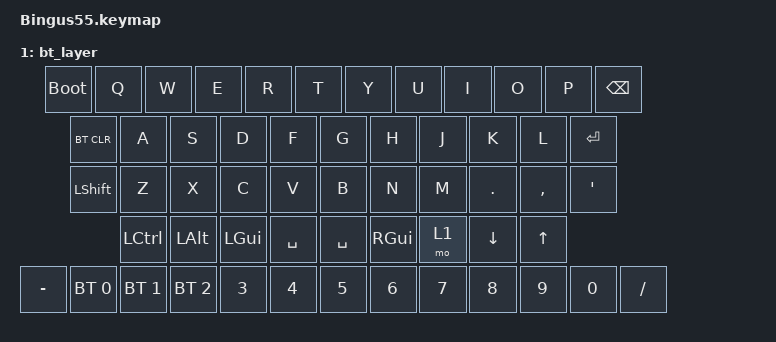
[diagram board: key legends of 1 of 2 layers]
#include <dt-bindings/zmk/keys.h>
#include <dt-bindings/zmk/bt.h>
#include <behaviors.dtsi>

/ {
    keymap {
            compatible = "zmk,keymap";

            default_layer {
                bindings = <
                &kp ESC &kp Q &kp W &kp E &kp R &kp T &kp Y &kp U &kp I &kp O &kp P &kp BSPC
		        &kp TAB &kp A &kp S &kp D &kp F &kp G &kp H &kp J &kp K &kp L &kp ENTER 
	            &kp LSHIFT &kp Z &kp X &kp C &kp V &kp B &kp N &kp M &kp DOT &kp COMMA &kp APOS 
		        &kp LCTRL &kp LALT &kp LGUI &kp SPACE &kp SPACE &kp RGUI &mo 1 &kp LEFT &kp RIGHT
		        &kp MINUS &kp N1 &kp N2 &kp N3 &kp N4 &kp N5 &kp N6 &kp N7 &kp N8 &kp N9 &kp N0 &kp SLASH
                >;
            };

            bt_layer {
                bindings = <
                    &bootloader &kp Q &kp W &kp E &kp R &kp T &kp Y &kp U &kp I &kp O &kp P &kp BSPC
		        &bt BT_CLR &kp A &kp S &kp D &kp F &kp G &kp H &kp J &kp K &kp L &kp ENTER 
	            &kp LSHIFT &kp Z &kp X &kp C &kp V &kp B &kp N &kp M &kp DOT &kp COMMA &kp APOS 
		        &kp LCTRL &kp LALT &kp LGUI &kp SPACE &kp SPACE &kp RGUI &mo 1 &kp DOWN &kp UP
		        &kp MINUS &bt BT_SEL 0 &bt BT_SEL 1 &bt BT_SEL 2 &kp N3 &kp N4 &kp N5 &kp N6 &kp N7 &kp N8 &kp N9 &kp N0 &kp SLASH
                >;
            };
    };
};
